# nrf7140_wificore register map
Vendor: Nordic Semiconductor; Series: nRF71; File version: 1
Registers are 32-bit, read-write, reset 0x0 unless marked. A register's access mark holds for its fields unless they carry their own. Offsets are from the block's base; [hi:lo] are bit positions; lines under a group give offsets from that group; {n}, {i} and the like mark numbered series; 'fields as' and 'values as' point back to an identical list; <NAME> marks a mode.

## RPUPHY (part 2 of 8) — WIFICore RPU PHY peripherals
Base 0x48080000; alternate view of RPUMAC
0x7000 SCP group — Unspecified
  0x150 RESAMPLERCOEFFADDR — SCP RESAMPLERCOEFF ADDR
    [5:0] SCPRESAMPLERCOEFFADDR — Address for coefficient of resampler filter.
  0x154 RESAMPLERCOEFFDATA — SCP RESAMPLERCOEFF DATA
    [13:0] SCPRESAMPLERCOEFFDATA — Data for coefficient of resampler filter in 2's complement format.SCP_RESAMPLERCOEFF_ADDR automatically increments following write.
  0x158 RESAMPLINGTIMEACCUMENABLE — SCP RESAMPLING TIME ACCUM ENABLE
    [0] TIMEACCUMENABLE — Enable snapshot of resampler time accumulator to register TIME_ACCUM when the ED/AGC enables the SCP output (requires WLAN_EDAGC_START=1).Automatically cleared once the snapshot is captured.
  0x15C RESAMPLINGTIMEACCUM ro — SCP RESAMPLING TIME ACCUM
    [23:0] TIMEACCUM — Contains a snapshot of the resampler time accumulator captured when the ED/AGC enables the SCP output (when enabled with TIME_ACCUM_ENABLE=1).The snaphot stores the most significant 24-bits of the fractional part of the resampler time accumulator.Note that TIME_ACCUM_ENABLE is cleared once the snapshot is captured.
  0x160 SAMPLENUMBER ro — SCP SAMPLE NUMBER
    [15:0] SAMPLENUM — The current state of the sample counter for the active frame.
  0x164 SYMBOLNUMBER ro — SCP SYMBOL NUMBER
    [15:0] SYMBOLNUM — The current state of the symbol counter for the active frame.
  0x168 SAMPLENUMBERA ro — SCP SAMPLE NUMBER A
    [15:0] SAMPLENUMBERA — The current state of the sample counter for frame A.
  0x16C SYMBOLNUMBERA — SCP SYMBOL NUMBER A
    [15:0] SYMBOLNUMBERA — The current state of the symbol counter for frame A.Can be written for immediate symbol counter update.
  0x170 SAMPLENUMBERB ro — SCP SAMPLE NUMBER B
    [15:0] SAMPLENUMBERB — The current state of the sample counter for frame B.
  0x174 SYMBOLNUMBERB — SCP SYMBOL NUMBER B
    [15:0] SYMBOLNUMBERB — The current state of the symbol counter for frame B.Can be written for immediate symbol counter update.
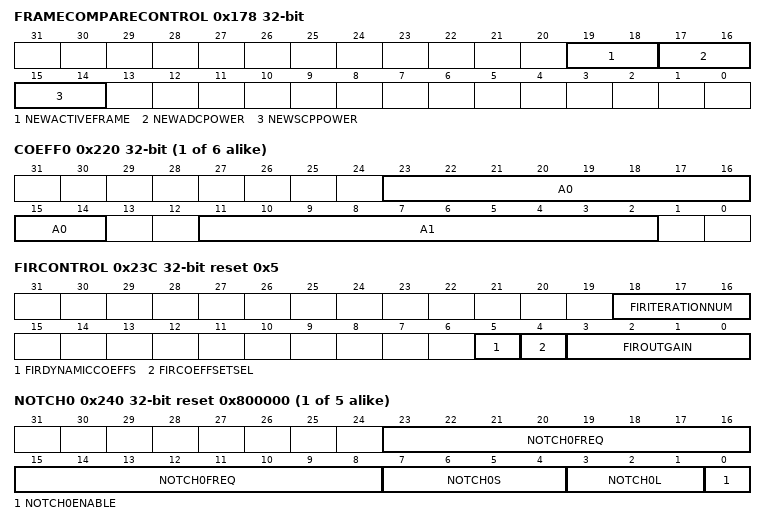
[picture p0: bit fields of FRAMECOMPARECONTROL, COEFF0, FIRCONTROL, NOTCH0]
  0x178 FRAMECOMPARECONTROL — SCP FRAME COMPARE CONTROL
    [19:18] NEWACTIVEFRAME — This field determines which will be the active frame following the next occurrence of the frame COMPARE_EVENT.
      0=NoChange; 1=NoChange1; 2=FrameAActive; 3=FrameBActive
    [17:16] NEWADCPOWER — This field determines the power state of the ADC following the next occurrence of the frame COMPARE_EVENT.
      0=NoChange; 1=LowPowerMode; 2=PowerOn; 3=PowerOff
    [15:14] NEWSCPPOWER — This field determines the power state of the SCP following the next occurrence of the frame COMPARE_EVENT.
      0=NoChange; 1=LowPowerMode; 2=PowerOn; 3=PowerOff
  0x17C FRAMECOMPARESYMBOL — SCP FRAME COMPARE SYMBOL
    [23:8] COMPARESYMBOLA — COMPARE_EVENT is asserted whenever the following condition is true:SYMBOL_NUMBER_A = COMPARE_SYMBOL_AandSAMPLE_NUMBER_A = COMPARE_SAMPLE_A.This will cause the assertion of IRQ_SCP if COMPARE_ENABLE is set.
  0x180 FRAMECOMPARESAMPLE — SCP FRAME COMPARE SAMPLE
    [23:8] COMPARESAMPLEA — COMPARE_EVENT is asserted whenever the following condition is true:SYMBOL_NUMBER_A = COMPARE_SYMBOL_AandSAMPLE_NUMBER_A = COMPARE_SAMPLE_A.This will cause the assertion of IRQ_SCP if COMPARE_ENABLE is set.
  0x188 SYMFIFOOUT ro — SCP SYM FIFO OUT
    [15:0] SYMFIFOOUT — The symbol counter value for the current DMA output.
  0x18C TBUSFIFOCOUNT ro — SCP TBUS FIFO COUNT
    [8:0] TBUSFIFOCOUNT — The number of symbols that have are stored in the TBus output FIFO.
  0x1A0 SYMBOLPERIODA — SCP SYMBOL PERIOD A
    [23:8] SYMBOLPERIODA — The number of SCP samples between the starts of two successive symbols inframe A. Must be > 1 in current implementation for DMA synchronization to work.Note that setting this register sets SYMBOL_PERIOD_ADJUST_A to the same value.
  0x1A4 FRAMESYMSA — SCP FRAME SYMS A
    [23:8] FRAMESYMSA — The number of symbols in frame A.Note that setting this register sets FRAME_SYMS_ADJUST_A to the same value.
  0x1A8 FINALPERIODA — SCP FINAL PERIOD A
    [23:8] FINALPERIODA — The number of SCP samples during the last symbol of frame A.Note that setting this register sets FINAL_PERIOD_ADJUST_A to the same value.
  0x1AC SYMBOLPERIODADJUSTA — SCP SYMBOL PERIOD ADJUST A
    [23:8] SYMBOLPERIODADJUSTA — The value written to this field defines the duration of the next symbol only. At the end of the adjusted symbol this field is automatically set to equal the value of SYMBOL_PERIOD_A.
  0x1B0 FRAMESYMSADJUSTA — SCP FRAME SYMS ADJUST A
    [23:8] FRAMESYMSADJUSTA — The value written to this field defines the number of symbols in the current frame only. At the end of the current frame this field is automatically set to equal the value of FRAME_SYMS_A.
  0x1B4 FINALPERIODADJUSTA — SCP FINAL PERIOD ADJUST A
    [23:8] FINALPERIODADJUSTA — The value written to this field defines the duration of the last symbol of the current frame only. At the end of the current frame this field is automatically set to equal the value of FINAL_PERIOD_A.
  0x1B8 APPLYPARAMETERSA — SCP APPLY PARAMETERS A
    [23:8] APPLYPARAMETERSA — If the SYNCHRONISE_UPDATES bit is set in the Control register, a number of parameters are updated synchronously when the sample number is equal to (APPLY_PARAMETERS_A - 1). Thus, with the control bit set, writes to the parameter fields are held off until SAMPLE_NUMBER_A = (APPLY_PARAMETERS_A - 1). If SYNCHRONISE_UPDATES is not set, updates to the parameters occur immediately that they are written to the appropriate registers.The following parameter updates are synchronized:- GAIN_CONTROL_1- GAIN_CONTROL_2- OFFSET_CONTROL_1- OFFSET_CONTROL_2- DC_OFFSET_I- DC_OFFSET_Q- COARSE_GAIN- I_GAIN- Q_GAIN- I_TO_Q_GAIN- FS- FC
  0x1E0 SYMBOLPERIODB — SCP SYMBOL PERIOD B
    [23:8] SYMBOLPERIODB — The number of SCP samples between the starts of two successive symbols inframe B. Must be > 1 in current implementation for DMA synchronization to work.Note that setting this register sets SYMBOL_PERIOD_ADJUST_B to the same value.
  0x1E4 FRAMESYMSB — SCP FRAME SYMS B
    [23:8] FRAMESYMSB — The number of symbols in frame B.Note that setting this register sets FRAME_SYMS_ADJUST_B to the same value.
  0x1E8 FINALPERIODB — SCP FINAL PERIOD B
    [23:8] FINALPERIODB — The number of SCP samples during the last symbol of frame B.Note that setting this register sets FINAL_PERIOD_ADJUST_B to the same value.
  0x1EC SYMBOLPERIODADJUSTB — SCP SYMBOL PERIOD ADJUST B
    [23:8] SYMBOLPERIODADJUSTB — The value written to this field defines the duration of the next symbol only. At the end of the adjusted symbol this field is automatically set to equal the value of SYMBOL_PERIOD_B.
  0x1F0 FRAMESYMSADJUSTB — SCP FRAME SYMS ADJUST B
    [23:8] FRAMESYMSADJUSTB — The value written to this field defines the number of symbols in the current frame only. At the end of the current frame this field is automatically set to equal the value of FRAME_SYMS_B.
  0x1F4 FINALPERIODADJUSTB — SCP FINAL PERIOD ADJUST B
    [23:8] FINALPERIODADJUSTB — The value written to this field defines the duration of the last symbol of the current frame only. At the end of the current frame this field is automatically set to equal the value of FINAL_PERIOD_B.
  0x1F8 APPLYPARAMETERSB — SCP Apply Parameters B
    [23:8] APPLYPARAMETERSB — If the SYNCHRONISE_UPDATES bit is set in the Control register, a number of parameters are updated synchronously when the sample number is equal to (APPLY_PARAMETERS_B - 1). Thus, with the control bit set, writes to the parameter fields are held off until SAMPLE_NUMBER_B = (APPLY_PARAMETERS_B - 1). If SYNCHRONISE_UPDATES is not set, updates to the parameters occur immediately that they are written to the appropriate registers.The following parameter updates are synchronized:The following parameter updates are synchronized:- GAIN_CONTROL_1- GAIN_CONTROL_2- OFFSET_CONTROL_1- OFFSET_CONTROL_2- DC_OFFSET_I- DC_OFFSET_Q- COARSE_GAIN- I_GAIN- Q_GAIN- I_TO_Q_GAIN- FS- FC
  {0x220+4j} COEFF{j} (j=0..5) — SCP COEFF {j}
    [23:14] A{2j} — Coefficient of final decimation filter in 2's complement format.Only valid for 12-bit SCP, SCP_COEFF_ADDR/DATA must be used for 16-bit SCP.NOTE: use FIR_COEFF_SET_SEL to select the coefficients set.
    [11:2] A{2j+1} — Coefficient of final decimation filter in 2's complement format.Only valid for 12-bit SCP, SCP_COEFF_ADDR/DATA must be used for 16-bit SCP.NOTE: use FIR_COEFF_SET_SEL to select the coefficients set.
  0x238 FIRBYPASS — SCP FIR BYPASS
    [23] FIRBYPASS — Used to set the bypass mode of the FIR block.When bypass is set the FIR block is powered down and data passes around it unaltered.When set to Normal the block operates as programmed by the registers that control it.
      0=NormalOperation; 1=Block Bypassed (overrules any other block settings)
  0x23C FIRCONTROL reset 0x5 — SCP FIR CONTROL
    [18:16] FIRITERATIONNUM — Number of FIR filter iteration cycles to perform per sample.The FIR filter contains a filter with 24 taps.Making use of the same filter for multiple cycles creates a virtual FIR filter with more taps.This field should be set as floor (FIR_VIRTUAL_TAP_NUM / FIR_REAL_TAP_NUM)-1, where FIR_VIRTUAL_TAP_NUM refers to the number of taps that are needed for the current application.Only valid for 16-bit SCP.
    [5] FIRDYNAMICCOEFFS — Enable dynamic decimation FIR coefficients selection (set 0 for OFDM, set 1 for DSSS).When disabled the set 0 is only used.
    [4] FIRCOEFFSETSEL — Selects Decimating FIR Coefficients set (reading and writing):
      0=OfdmSet; 1=DsssSet
    [3:0] FIROUTGAIN — Selects Decimating FIR output gain to normalise the gain range (2.4 to 23):0. Gain of 1/32 (>>14 + x) is applied to the output of Final Stage Decimation - FIR Filter1. Gain of 1/16 (>>13 + x) is applied to the output of Final Stage Decimation - FIR Filter2. Gain of 1/8(>>12 + x) is applied to the output of Final Stage Decimation - FIR Filter3. Gain of 1/4(>>11 + x) is applied to the output of Final Stage Decimation - FIR Filter4. Gain of 1/2(>>10 + x) is applied to the output of Final Stage Decimation - FIR Filter5. Gain of 1.0(>>9 + x)is applied to the output of Final Stage Decimation - FIR Filter (default)6. Gain of 2.0(>>8 + x)is applied to the output of Final Stage Decimation - FIR Filter7. Gain of 4.0(>>7 + x)is applied to the output of Final Stage Decimation - FIR Filter8. Gain of 8.0(>>6 + x)is applied to the output of Final Stage Decimation - FIR Filter9. Gain of 16.0 (>>5 + x)is applied to the output of Final Stage Decimation - FIR FilterWhere x is 0 for 12-bit SCP and 7 for 16-bit SCP.
  {0x240+4j} NOTCH{j} reset 0x800000 (j=0..4) — SCP NOTCH {j}
    [23:8] NOTCH{j}FREQ — Defines the centre frequency of the first notch of the ACI / CCI filter.FREQ is a signed (2's complement) number, where the full-scale negative value represents a frequency of - R_CLK/2 (where R_CLK is the output sample rate).
    [7:4] NOTCH{j}S — Notch filter gain shift value
      0=SHIFT=14 -10 dB BW ~= Fs / 20000for L=0; 1=SHIFT=13 -10 dB BW ~= Fs / 10000for L=0; 2=SHIFT=12 -10 dB BW ~= Fs / 5000for L=0; 3=SHIFT=11 -10 dB BW ~= Fs / 2500for L=0; 4=SHIFT=10 -10 dB BW ~= Fs / 1250for L=0; 5=SHIFT=9 -10 dB BW ~= Fs / 600for L=0; 6=SHIFT=8 -10 dB BW ~= Fs / 300for L=0; 7=SHIFT=7 -10 dB BW ~= Fs / 140for L=0; 8=SHIFT=6 -10 dB BW ~= Fs / 65for L=0; 9=SHIFT=5 -10 dB BW ~= Fs / 28for L=0; 10=SHIFT=4 -10 dB BW ~= Fs / 9for L=0
    [3:1] NOTCH{j}L — Notch filter gain linear valueNOTE: these multiplier values become increasingly inaccurate as the value of SHIFT is reduced below 8. For values of SHIFT<8, it is advisable to evaluate the notch bandwidth using simulation or calculation.
      {v}=L={v} -10 dB BW ~={v+8}/8 * BWfor L=0 (v=0..7)
    [0] NOTCH{j}ENABLE
      0=Disable the notch filter (NOTE: the NotchEnergy register is unaffected); 1=EnableTheNotchFilter
  0x254 NOTCHENERGY0I — SCP NOTCHENERGY 0 I
    [23:7] IENERGY0 — Represents a measure of the negated in-phase signal component suppressed by notch filter 0 in 2' complement format.13-bit value sign extended to 16 bits in bits 23:8 valid for 12-bit SCP, 17-bit value in bits 23:7 valid for 16-bit SCP.
  {0x258+8j} NOTCHENERGY{j}Q (j=0..4) — SCP NOTCHENERGY {j} Q
    [23:7] QENERGY{j} — Represents a measure of the negated quadrature signal component suppressed by notch filter {j} in 2' complement format.This register will hold the current Q value after a read command is issued to the SCP_NOTCHENERGY_{j}_I register until this register is read.13-bit value sign extended to 16 bits in bits 23:8 valid for 12-bit SCP, 17-bit value in bits 23:7 valid for 16-bit SCP.
  0x25C NOTCHENERGY1I — SCP NOTCHENERGY 1 I
    [23:7] IENERGY1 — Represents a measure of the negated in-phase signal component suppressed by notch filter 1 in 2's complement format.13-bit value sign extended to 16 bits in bits 23:8 valid for 12-bit SCP, 17-bit value in bits 23:7 valid for 16-bit SCP.
  {0x254+8j} NOTCHENERGY{j}I (j=2..4) — SCP NOTCHENERGY {j} I
    [23:7] IENERGY{j} — Represents a measure of the negated in-phase signal component suppressed by notch filter {j} in 2' complement format.13-bit value sign extended to 16 bits in bits 23:8 valid for 12-bit SCP, 17-bit value in bits 23:7 valid for 16-bit SCP.
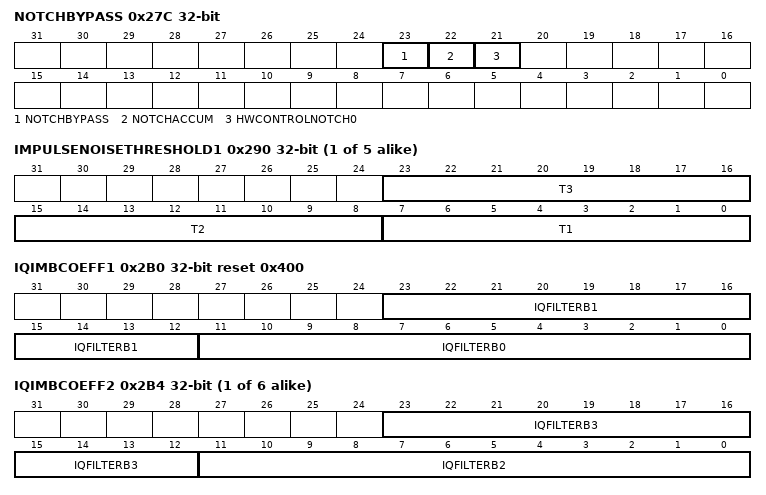
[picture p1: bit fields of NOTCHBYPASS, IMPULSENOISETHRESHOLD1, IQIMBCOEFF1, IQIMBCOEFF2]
  0x27C NOTCHBYPASS — SCP NOTCH BYPASS
    [23] NOTCHBYPASS — Used to set the bypass mode of the Notch filter block.When bypass is set the Notch filter block is powered down and data passes around it unaltered.When set to Normal the block operates as programmed by the registers that control it.
      values as SCP.FIRBYPASS.FIRBYPASS
    [22] NOTCHACCUM — Determines whether notch phase accumulators are reset when NOTCHn_FREQ registers are written to.
      0=Reset accumulation when NOTCHn_FREQ registers are written to; 1=Continue accumulation when NOTCHn_FREQ registers are written to
    [21] HWCONTROLNOTCH0 — Determine the Notch filter 0 enabling/disabling control mode:0. Notch filter 0 is enabled if SCP_NOTCH_0.NOTCH0_ENABLE register field is set.1. Notch filter 0 is dynamically controlled using DSSS or OFDM information from ED block: enable notch when DSSS packet is detected, disable when OFDM packet is detected.*Note: mode 1 requires SCP_NOTCH_0.NOTCH0_ENABLE = 1 and SCP_NOTCH_BYPASS.NOTCH_BYPASS = 0
  0x280 IMPULSENOISECONTROL — SCP IMPULSE NOISE CONTROL
    [23] NOISEFILTERENABLE
      0=I/Q samples are not deleted but counters operate normally; 1=I/Q samples are deleted as indicated by deletion logic
  0x284 IMPULSENOISEBURSTCOUNT ro — SCP IMPULSE NOISE BURST COUNT
    [15:8] NOISEBURSTCOUNT — The number of SCP sample bursts deleted by the impulse noise filter.This value is latched and held when AGC_COUNTS_EVENT is asserted.
  0x288 IMPULSENOISESAMPLECOUNT ro — SCP IMPULSE NOISE SAMPLE COUNT
    [15:8] NOISESAMPLECOUNT — The number of SCP samples deleted by the impulse noise filter.This value is latched and held when AGC_COUNTS_EVENT is asserted.
  0x28C IMPULSENOISEENERGY ro — SCP IMPULSE NOISE ENERGY
    [23:8] NOISEENERGY — The sum of energy in all the SCP samples deleted by the impulse noise filter.This value is latched and held when AGC_COUNTS_EVENT is asserted.
  {0x28C+4j} IMPULSENOISETHRESHOLD{j} (j=1..5) — SCP IMPULSE NOISE THRESHOLD {j}
    [23:16] T{3j} — Energy threshold for {3j}-sample window.Setting 0xFF disables this section.
    [15:8] T{3j-1} — Energy threshold for {3j-1}-sample window.Setting 0xFF disables this section.
    [7:0] T{3j-2} — Energy threshold for {3j-2}-sample window.Setting 0xFF disables this section.
  0x2A4 IMPULSENOISETHRESHOLD6 — SCP IMPULSE NOISE THRESHOLD 6
    [23:16] T16 — Energy threshold for 16-sample window.Setting 0xFF disables this section.
  0x2A8 IMPULSEFILTERBYPASS — SCP IMPULSE FILTER BYPASS
    [23] IMPBYPASS — Used to set the bypass mode of the Impulse filter block.When bypass is set the Impulse filter block is powered down and data passes around it unaltered.When set to Normal the block operates as programmed by the registers that control it.
      values as SCP.FIRBYPASS.FIRBYPASS
  0x2AC IQIMBINPHASEDLY — SCP IQ IMB INPHASE DLY
    [3:0] IQINPHASEDELAY — Delay line for Inphase stream. This is a unsigned value.The maximum supported value is 14.Relevant when IQ_IMBALANCE_BYPASS = 0.
  0x2B0 IQIMBCOEFF1 reset 0x400 — SCP IQ IMB COEFF1
    [23:12] IQFILTERB1 — Filter Coefficient B1 for Quadrature phase stream. This is a Q10 format (i.e. output of filter is right-shifted by 10 bits) 2's complement value.Relevant when IQ_IMBALANCE_BYPASS = 0.
    [11:0] IQFILTERB0 — Filter Coefficient B0 for Quadrature phase stream. This is a Q10 format (i.e. output of filter is right-shifted by 10 bits) 2's complement value.Relevant when IQ_IMBALANCE_BYPASS = 0.
  {0x2AC+4j} IQIMBCOEFF{j} (j=2..7) — SCP IQ IMB COEFF{j}
    [23:12] IQFILTERB{2j-1} — Filter Coefficient B{2j-1} for Quadrature phase stream. This is a Q10 format (i.e. output of filter is right-shifted by 10 bits) 2's complement value.Relevant when IQ_IMBALANCE_BYPASS = 0.
    [11:0] IQFILTERB{2j-2} — Filter Coefficient B{2j-2} for Quadrature phase stream. This is a Q10 format (i.e. output of filter is right-shifted by 10 bits) 2's complement value.Relevant when IQ_IMBALANCE_BYPASS = 0.
  0x2CC IQIMBCOEFF8 — SCP IQ IMB COEFF8
    [11:0] IQFILTERB14 — Filter Coefficient B14 for Quadrature phase stream. This is a Q10 format (i.e. output of filter is right-shifted by 10 bits) 2's complement value.Relevant when IQ_IMBALANCE_BYPASS = 0.
  0x2D0 IQIMBBYPASS — SCP IQ IMB BYPASS
    [16] IQIMBALANCEBYPASS — Used to set the bypass mode of the IQ imbalance compensation block:
      0=IQ imbalance compensation is active; 1=IQ imbalance compenstation block is powered down and data passes around it unaltered
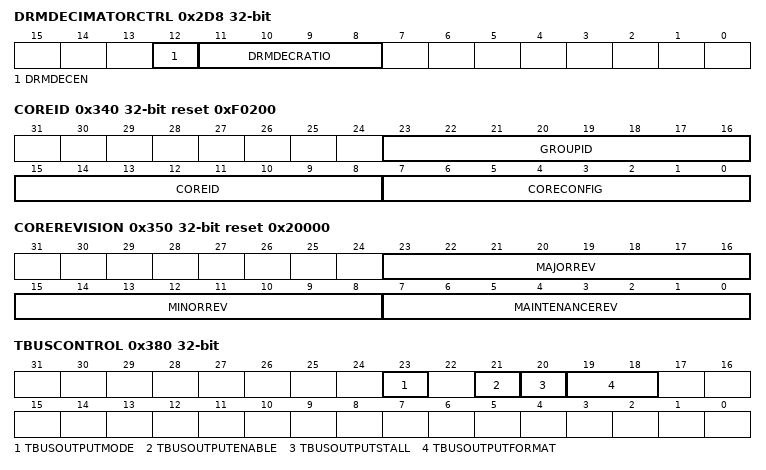
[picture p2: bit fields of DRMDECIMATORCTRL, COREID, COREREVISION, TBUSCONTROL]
  0x2D8 DRMDECIMATORCTRL — SCP DRM DECIMATOR CTRL
    [12] DRMDECEN
      0=BypassDrmDecimator; 1=EnableDecimation
    [11:8] DRMDECRATIO — Decimation ratio (if DRM_DEC_EN is set):0: Decimate by 1 (no decimation)1: Decimate by 215: Decimate by 16
  {0x2E0+0xC*j} EARLYGAINLUT[{j}] (j=0..7) group — Unspecified
    0x00 EARLYFINEGAINI reset 0x200000 — Description cluster: SCP EARLY FINE GAIN I
      [23:10] EARLYIGAIN — 2's complement value that multiplies I value from SCP.This is a linear gain where 0x800 represents the 0dB point, thus the fine gain is EARLY_I_GAIN/0x800.Bits 23:13 valid for 12-bit SCP, bits 23:10 valid for 16-bit SCP.
    0x04 EARLYFINEGAINQ reset 0x200000 — Description cluster: SCP EARLY FINE GAIN Q
      [23:10] EARLYQGAIN — 2's complement value that multiplies Q value from SCP.This is a linear gain where 0x800 represents the 0dB point, thus the fine gain is EARLY_Q_GAIN/0x800.Bits 23:13 valid for 12-bit SCP, bits 23:10 valid for 16-bit SCP.
    0x08 EARLYANGLEIQ — Description cluster: SCP EARLY ANGLE IQ
      [23:10] EARLYITOQGAIN — 2's complement value that multiplies I value before addition to Q value in the early gain block.Qout = Q + (I * EARLY_I_TO_Q_GAIN >> 13).Bits 23:13 valid for 12-bit SCP, bits 23:10 valid for 16-bit SCP.
  0x340 COREID ro reset 0xF0200 — SCP CORE ID
    [23:16] GROUPID — Identifies core as part of an IMG IP family group.
    [15:8] COREID — Identifies the member of the IP group.
    [7:0] CORECONFIG — Configuration of the core.
  0x350 COREREVISION ro reset 0x20000 — SCP CORE REVISION
    [23:16] MAJORREV — Family Major Release Revision
    [15:8] MINORREV — Core Minor Release Revision
    [7:0] MAINTENANCEREV — Maintenance Release Revision
  0x360 GNSSOUTPUTFORMAT — SCP GNSS OUTPUT FORMAT
    [2:0] GNSSOUTPUTFORMAT — SCP, GNSS Location Core output format selection.0:1x I/Q pair(12-bits per component)This represents standard SCP operation.1:3x I/Q pairs(4-bits per component)2:4x I/Q pairs(3-bits per component)3:6x I/Q pairs(2-bits per component)4: 12x I/Q pairs(1-bitper component)Other values are reserved and must not be used.Where a non-zero value is set in this register the 12-bit samples in each pair are reduced to the k-bit width indicated by selecting the k MSBs from each 12-bit sample.Setting this register to a non-zero value assumes TBUS_OUTPUT_FORMAT=0
  0x380 TBUSCONTROL — SCP TBUS CONTROL
    [23] TBUSOUTPUTMODE — Used to enable output to TBus:
      0=OutputToTbusDisabled; 1=OutputToTbusEnabled
    [21] TBUSOUTPUTENABLE — Used to enable or disable output of next symbol to TBus:
      0=Output to TBus disabled at end of next symbol; 1=Output to TBus enabled at start of next symbol
    [20] TBUSOUTPUTSTALL — Used to enable or disable stalling of SCP when output FIFO is full:
      0=Stalling of SCP disabled when output FIFO is full.TBUS_OVERFLOW_EVENT flagged when SCP output overflows TBus output FIFO.OVERFLOW_EVENT can also be flagged when input data rate too high for enabled processing (i.e. due to re-sample factor, or enabling of notch/impulse filters).; 1=Stalling of SCP enabled when output FIFO is full.TBUS_OVERFLOW_EVENT not flagged, only OVERFLOW_EVENT flagged when input data rate too high for enabled processing (i.e. due to re-sample factor, or enabling of notch/impulse filters), or as a result of EDC TBus job rate being too slow.
    [19:18] TBUSOUTPUTFORMAT — Used to select TBus output format:0 : 12-bit real in upper and 12-bit imaginary in lower 24 bits of TBus output (default).1 : Alternating 16-bit imaginary followed by 16-bit real, left aligned in 24-bits of output TBus.8-bit lsbs are zero padded and full 24 bits transferred to memory by EDC for processing as 24-bit double by MCP.This case is only relevant on 16-bit SCPs.Note reference to this register in the description of register GNSS_OUTPUT_FORMAT.2 : Alternating 16-bit imaginary followed by 16-bit real, right aligned in 24-bits of output TBus.Sign extended to 24 bits but in practice only lower 16 bits will be transferred to memory by EDC for processing as 32-bit complex by MCU.This case is only relevant on 16-bit SCPs.Note reference to this register in the description of register GNSS_OUTPUT_FORMAT.3 : Alternating 12-bit real followed by 12-bit imaginary, where each 12-bit word is left shifted by 4 and signed extended to 24-bits.
  0x390 ISCRCONTROL — SCP ISCR CONTROL
    [8] SCPISCRENABLE — Control for ISCR Counter:
      0=Disable; 1=Enable
  0x394 ISCRCOUNTER0 — SCP ISCR COUNTER0
    [23:0] ISCRCOUNTERLOW — lowest 24 bits of iscr_counter value clocked at scp output rate. Writable register to manually set the low bits of the iscr counter value
  0x398 ISCRCOUNTER1 — SCP ISCR COUNTER1
    [23:0] ISCRCOUNTERHIGH — highest 24 bits of iscr_counter value clocked at scp output rate. Writable register to manually set the high bits fo the iscr counter value
  0x39C ISCRSTATUS0 ro — SCP ISCR STATUS0
    [23:0] ISCRSYMSTARTLOW — lowest 24 bits of iscr_counter value at start of the last scp symbol.
  0x3A0 ISCRSTATUS1 ro — SCP ISCR STATUS1
    [23:0] ISCRSYMSTARTHIGH — highest 24 bits of iscr_counter value at start of the last scp symbol.
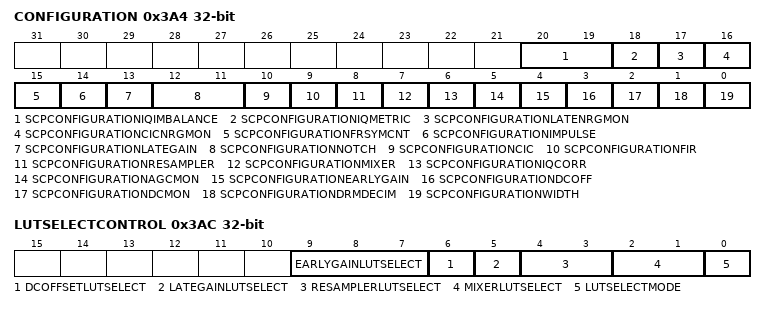
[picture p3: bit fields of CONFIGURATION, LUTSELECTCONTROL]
  0x3A4 CONFIGURATION ro — SCP CONFIGURATION
    [20:19] SCPCONFIGURATIONIQIMBALANCE — IQ level imbalance configuration:
      0=Disabled; 1=Enabled before resampler; 2=Enabled after resampler
    [18] SCPCONFIGURATIONIQMETRIC — IQ level imbalance estimation metric generation configuration:
      0=Disabled; 1=Enabled
    [17] SCPCONFIGURATIONLATENRGMON — Energy Monitor on input to Late Gain configuration:
      0=Disabled; 1=Enabled
    [16] SCPCONFIGURATIONCICNRGMON — Energy Monitor on input to CIC Decimator configuration:
      0=Disabled; 1=Enabled
    [15] SCPCONFIGURATIONFRSYMCNT — Frame counters, Symbol metric configuration:
      0=Disabled; 1=Enabled
    [14] SCPCONFIGURATIONIMPULSE — Impulse noise configuration:
      0=Disabled; 1=Enabled
    [13] SCPCONFIGURATIONLATEGAIN — Late gain configuration:
      0=Disabled; 1=Enabled
    [12:11] SCPCONFIGURATIONNOTCH — Notch filter configuration:
      0=Disabled; 1=Enabled with throughput 6; 2=EnabledWithThroughpu2 (Enabled with throughput 2.)
    [10] SCPCONFIGURATIONCIC — CIC Decimation filter configuration:
      0=Disabled; 1=Enabled
    [9] SCPCONFIGURATIONFIR — FIR Decimation filter configuration:
      0=Disabled; 1=Enabled
    [8] SCPCONFIGURATIONRESAMPLER — Resampler stage configuration:
      0=Disabled; 1=Enabled
    [7] SCPCONFIGURATIONMIXER — Mixer stage configuration:
      0=Disabled; 1=Enabled
    [6] SCPCONFIGURATIONIQCORR — IQ correlatorconfiguration:
      0=Disabled; 1=Enabled
    [5] SCPCONFIGURATIONAGCMON — AGC monitor configuration:
      0=Disabled; 1=Enabled
    [4] SCPCONFIGURATIONEARLYGAIN — Early gain control configuration:
      0=Disabled; 1=Enabled
    [3] SCPCONFIGURATIONDCOFF — DC offset controlconfiguration:
      0=Disabled; 1=Enabled
    [2] SCPCONFIGURATIONDCMON — DC monitor configuration:
      0=Disabled; 1=Enabled
    [1] SCPCONFIGURATIONDRMDECIM — DRM decimator configuration:
      0=Disabled; 1=Enabled
    [0] SCPCONFIGURATIONWIDTH — Width configuration:
      0=12Bit; 1=16Bit
  0x3AC LUTSELECTCONTROL — SCP LUT SELECT CONTROL
    [9:7] EARLYGAINLUTSELECT — Early Gain LUT select value. Range 0 to 7.
    [6] DCOFFSETLUTSELECT — DC Offset LUT select value. Range 0 to 1.
    [5] LATEGAINLUTSELECT — Late Gain LUT select value. Range 0 to 1.
    [4:3] RESAMPLERLUTSELECT — Resampler LUT select value. Range 0 to 3.
    [2:1] MIXERLUTSELECT — Mixer LUT select value. Range 0 to 3.
    [0] LUTSELECTMODE — Mode for generation of LUT select signals:0: LUT select signals will be generated based on input signals andwrites to corresponding registers,1: LUT select signals will take value from register.
  {0x3B0+8j} LATEGAINLUT[{j}] (j=0..1) group — Unspecified
    0x00 LATEFINEGAINI reset 0x200000 — Description cluster: SCP LATE FINE GAIN I
      [23:13] LATEIGAIN — 2's complement value that multiplies I value from SCP. This is a linear gain where 0x100 represents the 0dB point, thus the fine gain is LATE_I_GAIN/0x100.
    0x04 LATEFINEGAINQ reset 0x200000 — Description cluster: SCP LATE FINE GAIN Q
      [23:13] LATEQGAIN — 2's complement value that multiplies Q value from SCP. This is a linear gain where 0x100 represents the 0dB point, thus the fine gain is LATE_Q_GAIN/0x100.
  {0x3C0+8j} MIXERLUT[{j}] (j=0..3) group — Unspecified
    0x00 LOBASE — Description cluster: SCP LO BASE
      [23:21] LOBASE — Local Oscillator base. This is an unsigned value which is combined with LO_CONTROL to generate the 26-bit control Fc:Fc = (LO_BASE << 23) + LO_CONTROLFc is in 2's complement signed format where its value represents numbers within the range -1 to 0.9999999. To convert a ratio into the 26-bit Fc, multiply by 2^25.The digitally generated Local Oscillator (LO) frequency used in the mixer section is equal to Fc * (IF Clock Frequency/2). Hence the full-scale negative value represents a frequency of -(IF Clock Frequency/2).The input signal is frequency translated such that input frequency F moves to a frequency of F + Local Oscillator (LO) Frequency.NOTE : a real IF input implicitly carries the inverse of its positive spectrum at negative frequencies. This means that a positive Fc applied to a real IF gives an inverted spectrum, and a negative Fc gives a non-inverted one. An SCP input contains independent positive and negative frequency components, so Fc cannot invert the spectrum.
    0x04 LOCONTROL — Description cluster: SCP LO CONTROL
      [23:0] LOCONTROL — Local Oscillator control. This is a 2's complement value which is combined with LO_BASE to generate the 26-bit control Fc:Fc = (LO_BASE << 23) + LO_CONTROL
  {0x3E0+8j} RESAMPLERLUT[{j}] (j=0..3) group — Unspecified
    0x00 RESAMPLINGFACTORBASE reset 0x800000 — Description cluster: SCP RESAMPLING FACTOR BASE
      [23:21] RESAMPBASE — Resampling factor base. This is an unsigned value which is combined with the 2's complement RESAMP_CONTROL to generate the 26-bit control Fs:Fs = (RESAMP_BASE << 23) + RESAMP_CONTROLFs is the sample conversion ratio (I / O) used in the sample rate conversion section of the SCP.Fs is an unsigned number, where the full-scale range of values is 1 / (2^25) to ((2^26) - 1) / (2^25) = 2.98023224E-08 to 1.99999997NOTE: To convert a ratio into the 26-bit Fs, multiply by 2^25
    0x04 RESAMPLINGFACTORCONTROL — Description cluster: SCP RESAMPLING FACTOR CONTROL
      [23:0] RESAMPCONTROL — Resampling factor control. This is a 2's complement value which is combined with RESAMP_BASE to generate the 26-bit control Fs:Fs = (RESAMP_BASE << 23) + RESAMP_CONTROL
